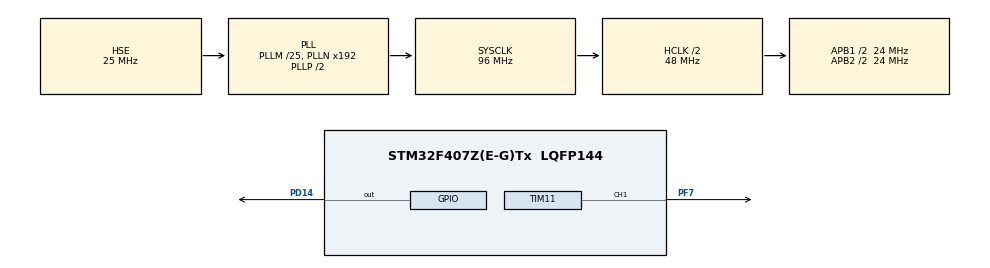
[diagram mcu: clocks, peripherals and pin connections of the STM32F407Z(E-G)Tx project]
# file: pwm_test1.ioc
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Mcu.Family=STM32F4
Mcu.Name=STM32F407Z(E-G)Tx
Mcu.Package=LQFP144
NVIC.PriorityGroup=NVIC_PRIORITYGROUP_4
NVIC.RCC_IRQn=true\:0\:0\:false\:false\:true\:true\:false
NVIC.TIM1_TRG_COM_TIM11_IRQn=true\:0\:0\:false\:false\:true\:true\:true
PA13.Mode=Serial_Wire
PA13.Signal=SYS_JTMS-SWDIO
PA14.Mode=Serial_Wire
PA14.Signal=SYS_JTCK-SWCLK
PC14-OSC32_IN.Mode=LSE-External-Oscillator
PC14-OSC32_IN.Signal=RCC_OSC32_IN
PC15-OSC32_OUT.Mode=LSE-External-Oscillator
PC15-OSC32_OUT.Signal=RCC_OSC32_OUT
PD14.Signal=GPIO_Output
PF7.Signal=S_TIM11_CH1
PH0-OSC_IN.Mode=HSE-External-Oscillator
PH0-OSC_IN.Signal=RCC_OSC_IN
PH1-OSC_OUT.Mode=HSE-External-Oscillator
PH1-OSC_OUT.Signal=RCC_OSC_OUT
ProjectManager.HeapSize=0x200
ProjectManager.StackSize=0x400
ProjectManager.TargetToolchain=TrueSTUDIO
RCC.48MHZClocksFreq_Value=48000000
RCC.AHBCLKDivider=RCC_SYSCLK_DIV2
RCC.AHBFreq_Value=48000000
RCC.APB1CLKDivider=RCC_HCLK_DIV2
RCC.APB1Freq_Value=24000000
RCC.APB1TimFreq_Value=48000000
RCC.APB2CLKDivider=RCC_HCLK_DIV2
RCC.APB2Freq_Value=24000000
RCC.APB2TimFreq_Value=48000000
RCC.CortexFreq_Value=48000000
RCC.HCLKFreq_Value=48000000
RCC.HSE_VALUE=25000000
RCC.HSI_VALUE=16000000
RCC.PLLM=25
RCC.PLLSourceVirtual=RCC_PLLSOURCE_HSE
RCC.SYSCLKFreq_VALUE=96000000
RCC.SYSCLKSource=RCC_SYSCLKSOURCE_PLLCLK
RCC.VCOOutputFreq_Value=192000000
SH.S_TIM11_CH1.0=TIM11_CH1,PWM Generation1 CH1
TIM11.AutoReloadPreload=TIM_AUTORELOAD_PRELOAD_ENABLE
TIM11.Channel=TIM_CHANNEL_1
TIM11.OCFastMode_PWM=TIM_OCFAST_DISABLE
TIM11.Period=1000
TIM11.Prescaler=48000
TIM11.Pulse=500
VP_TIM11_VS_ClockSourceINT.Mode=Enable_Timer
board=custom

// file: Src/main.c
/* USER CODE BEGIN Header */
/**
  ******************************************************************************
  * @file           : main.c
  * @brief          : Main program body
  ******************************************************************************
  * @attention
  *
  * <h2><center>&copy; Copyright (c) 2019 STMicroelectronics.
  * All rights reserved.</center></h2>
  *
  * This software component is licensed by ST under BSD 3-Clause license,
  * the "License"; You may not use this file except in compliance with the
  * License. You may obtain a copy of the License at:
  *                        opensource.org/licenses/BSD-3-Clause
  *
  ******************************************************************************
  */
/* USER CODE END Header */

#include "main.h"
#include "tim.h"
#include "gpio.h"

void SystemClock_Config(void);

int main(void)
{
  /* USER CODE BEGIN 1 */
  int test=0;
  /* USER CODE END 1 */

  /* MCU Configuration--------------------------------------------------------*/

  /* Reset of all peripherals, Initializes the Flash interface and the Systick. */
  HAL_Init();

  /* Configure the system clock */
  SystemClock_Config();

  /* Initialize all configured peripherals */
  MX_GPIO_Init();
  MX_TIM11_Init();
  /* USER CODE BEGIN 2 */
  HAL_TIM_PWM_Start(&htim11,TIM_CHANNEL_1);

  HAL_TIM_PWM_Start_IT(&htim11,TIM_CHANNEL_1);

  /* USER CODE END 2 */

  /* Infinite loop */
  /* USER CODE BEGIN WHILE */
  while (1)
  {
	  for(test=0;test<500;test++)
	  {
      __HAL_TIM_SET_COMPARE(&htim11,TIM_CHANNEL_1,test);
      HAL_Delay(10);
	  }
	  for(test=500;test>0;test--)
	  {
      __HAL_TIM_SET_COMPARE(&htim11,TIM_CHANNEL_1,test);
      HAL_Delay(10);
	  }
    /* USER CODE END WHILE */

  }
}

void SystemClock_Config(void)
{
  RCC_OscInitTypeDef RCC_OscInitStruct = {0};
  RCC_ClkInitTypeDef RCC_ClkInitStruct = {0};

  /** Configure the main internal regulator output voltage
  */
  __HAL_RCC_PWR_CLK_ENABLE();
  __HAL_PWR_VOLTAGESCALING_CONFIG(PWR_REGULATOR_VOLTAGE_SCALE1);
  /** Initializes the CPU, AHB and APB busses clocks
  */
  RCC_OscInitStruct.OscillatorType = RCC_OSCILLATORTYPE_HSE;
  RCC_OscInitStruct.HSEState = RCC_HSE_ON;
  RCC_OscInitStruct.PLL.PLLState = RCC_PLL_ON;
  RCC_OscInitStruct.PLL.PLLSource = RCC_PLLSOURCE_HSE;
  RCC_OscInitStruct.PLL.PLLM = 25;
  RCC_OscInitStruct.PLL.PLLN = 192;
  RCC_OscInitStruct.PLL.PLLP = RCC_PLLP_DIV2;
  RCC_OscInitStruct.PLL.PLLQ = 4;
  if (HAL_RCC_OscConfig(&RCC_OscInitStruct) != HAL_OK)
  {
    Error_Handler();
  }
  /** Initializes the CPU, AHB and APB busses clocks
  */
  RCC_ClkInitStruct.ClockType = RCC_CLOCKTYPE_HCLK|RCC_CLOCKTYPE_SYSCLK
                              |RCC_CLOCKTYPE_PCLK1|RCC_CLOCKTYPE_PCLK2;
  RCC_ClkInitStruct.SYSCLKSource = RCC_SYSCLKSOURCE_PLLCLK;
  RCC_ClkInitStruct.AHBCLKDivider = RCC_SYSCLK_DIV2;
  RCC_ClkInitStruct.APB1CLKDivider = RCC_HCLK_DIV2;
  RCC_ClkInitStruct.APB2CLKDivider = RCC_HCLK_DIV2;

  if (HAL_RCC_ClockConfig(&RCC_ClkInitStruct, FLASH_LATENCY_1) != HAL_OK)
  {
    Error_Handler();
  }
}

void Error_Handler(void)
{
}

/************************ (C) COPYRIGHT STMicroelectronics *****END OF FILE****/
